# AM13E23219 register map
Vendor: Texas Instruments; File version: 1.0
CPU: CM33 r0p1, little endian, MPU, FPU, VTOR, 4 interrupt priority bits
Registers are 32-bit, read-write, reset 0x0 unless marked. A register's access mark holds for its fields unless they carry their own. Offsets are from the block's base; [hi:lo] are bit positions; {n}, {i} and the like mark numbered series; 'fields as' and 'values as' point back to an identical list.

## SYSCTL (part 2 of 2) — SYSCTL module
Base 0x400AF000
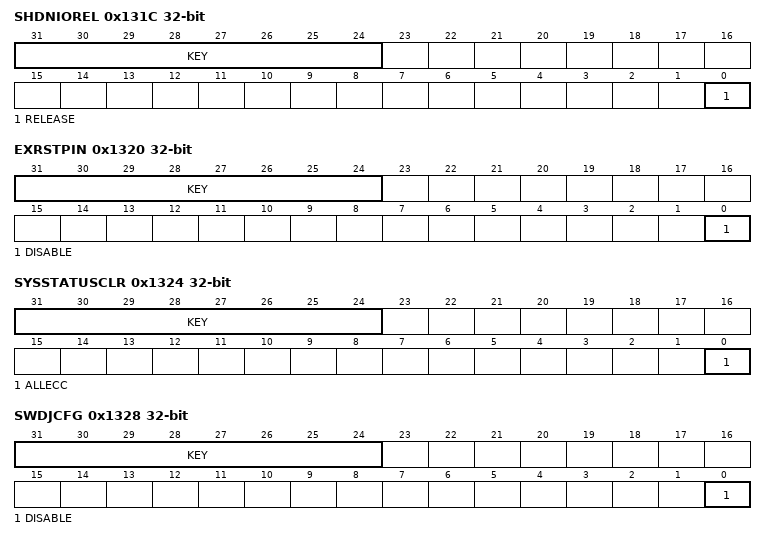
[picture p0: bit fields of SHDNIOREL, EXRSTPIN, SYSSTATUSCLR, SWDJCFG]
0x131C SHDNIOREL access per field — SHUTDOWN IO release control
  [31:24] KEY wo — Key which must be written for the write to take effect.
    145=KEY (Write key.)
  [0] RELEASE rw — Set RELEASE to release the IO after a SHUTDOWN mode exit.
    1=TRUE (Release IO)
0x1320 EXRSTPIN access per field — Disable the reset function of the NRST pin
  [31:24] KEY wo — Key which must be written for the write to take effect.
    30=KEY (Write key.)
  [0] DISABLE rw — Set DISABLE to disable the reset function of the NRST pin. Once set, this configuration is locked until the next POR.
    0=FALSE (Reset function of NRST pin is enabled); 1=TRUE (Reset function of NRST pin is disabled)
0x1324 SYSSTATUSCLR access per field — Clear sticky bits of SYSSTATUS
  [31:24] KEY wo — Key which must be written for the write to take effect.
    206=KEY (Write key.)
  [0] ALLECC rw — Set ALLECC to clear all ECC related SYSSTATUS indicators.
    1=CLEAR (Clear ECC error state)
0x1328 SWDJCFG access per field — Disable the SWD/JTAG function on the SWD/JTAG pins
  [31:24] KEY wo — Key which must be written for the write to take effect.
    98=KEY (Write key.)
  [0] DISABLE rw — Set DISABLE to disable the SWD/JTAG function on SWD/JTAG pins, allowing the SWD/JTAG pins to be used as GPIO.
    1=TRUE (Disable SWD/JTAG function on SWD/JTAG pins)
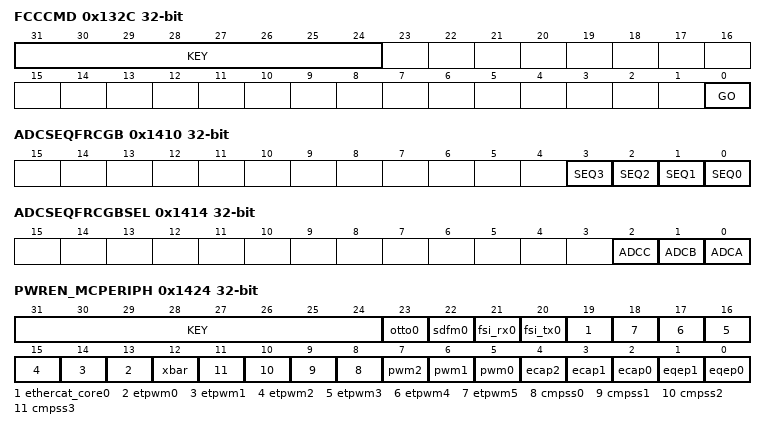
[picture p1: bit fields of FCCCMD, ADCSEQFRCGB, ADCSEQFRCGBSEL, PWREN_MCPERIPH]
0x132C FCCCMD access per field — Frequency clock counter start capture
  [31:24] KEY wo — Key which must be written for the write to take effect.
    14=KEY (Write key.)
  [0] GO rw — Set GO to start a capture with the frequency clock counter (FCC).
    1=TRUE
{0x1400+4i} SHUTDNSTORE{i} (i=0..3) — Shutdown storage memory (byte {i})
  [7:0] DATA — Shutdown storage byte {i}
0x1410 ADCSEQFRCGB — ADC Global Sequence Force
  [n] SEQ{n} (n=0..3) — Generate synchronous SW trigger for SEQ{n}
0x1414 ADCSEQFRCGBSEL — ADC Global Sequence Force Select
  [2] ADCC — Generate synchronous SW trigger for ADCC
  [1] ADCB — Generate synchronous SW trigger for ADCB
  [0] ADCA — Generate synchronous SW trigger for ADCA
0x1418 M33SPARESOCLOCK1 access not given — M33C1 Spare SOC LOCK Reg 1
0x141C M33SPARESOCLOCK2 access not given — M33C1 Spare SOC LOCK Reg 2
0x1420 SYSCTL_READ_REG access not given — Sysctl read only Reg
0x1424 PWREN_MCPERIPH access per field — Register to control the power state
  [31:24] KEY wo — Key which must be written for the write to take effect.
    38=KEY (Write key.)
  [23] otto0 rw — Enable the power to IP, KEY must be set to 26h to write to this bit
    0=Disable Power; 1=Enable Power
  [22] sdfm0 rw — Enable the power to IP, KEY must be set to 26h to write to this bit
    0=Disable Power; 1=Enable Power
  [21] fsi_rx0 rw — Enable the power to IP, KEY must be set to 26h to write to this bit
    0=Disable Power; 1=Enable Power
  [20] fsi_tx0 rw — Enable the power to IP, KEY must be set to 26h to write to this bit
    0=Disable Power; 1=Enable Power
  [19] ethercat_core0 rw — Enable the power to IP, KEY must be set to 26h to write to this bit
    0=Disable Power; 1=Enable Power
  [n+13] etpwm{n} rw (n=0..5) — Enable the power to IP, KEY must be set to 26h to write to this bit
    0=Disable Power; 1=Enable Power
  [12] xbar rw — Enable the power to IP, KEY must be set to 26h to write to this bit
    0=Disable Power; 1=Enable Power
  [n+8] cmpss{n} rw (n=0..3) — Enable the power to IP, KEY must be set to 26h to write to this bit
    0=Disable Power; 1=Enable Power
  [7] pwm2 rw — Enable the power to IP, KEY must be set to 26h to write to this bit
    0=Disable Power; 1=Enable Power
  [6] pwm1 rw — Enable the power to IP, KEY must be set to 26h to write to this bit
    0=Disable Power; 1=Enable Power
  [5] pwm0 rw — Enable the power to IP, KEY must be set to 26h to write to this bit
    0=Disable Power; 1=Enable Power
  [4] ecap2 rw — Enable the power to IP, KEY must be set to 26h to write to this bit
    0=Disable Power; 1=Enable Power
  [3] ecap1 rw — Enable the power to IP, KEY must be set to 26h to write to this bit
    0=Disable Power; 1=Enable Power
  [2] ecap0 rw — Enable the power to IP, KEY must be set to 26h to write to this bit
    0=Disable Power; 1=Enable Power
  [1] eqep1 rw — Enable the power to IP, KEY must be set to 26h to write to this bit
    0=Disable Power; 1=Enable Power
  [0] eqep0 rw — Enable the power to IP, KEY must be set to 26h to write to this bit
    0=Disable Power; 1=Enable Power
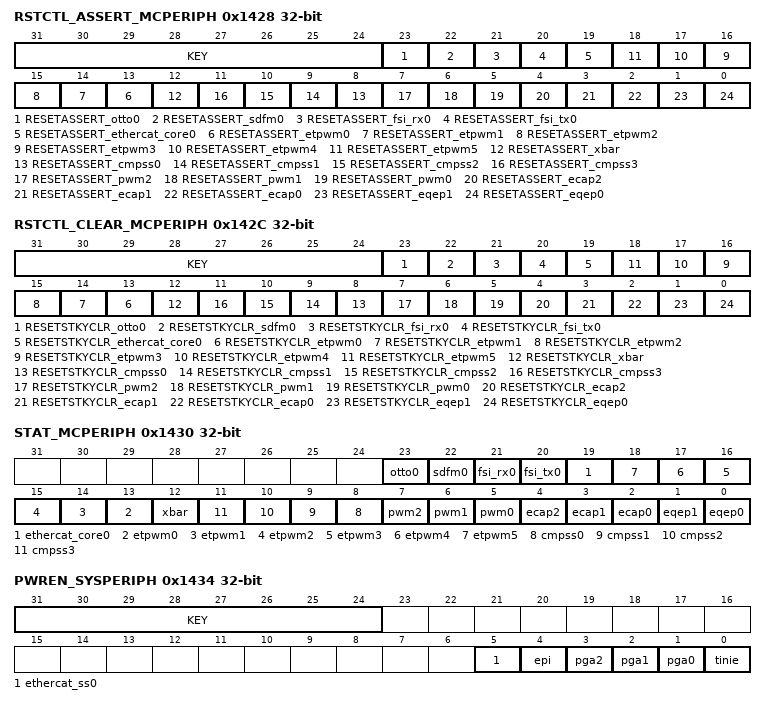
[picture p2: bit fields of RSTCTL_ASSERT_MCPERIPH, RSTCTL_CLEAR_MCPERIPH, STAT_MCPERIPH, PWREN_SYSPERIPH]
0x1428 RSTCTL_ASSERT_MCPERIPH access per field — rstctl assert register to control reset assertion - Write Only Register, Always Read as 0
  [31:24] KEY wo — Key which must be written for the write to take effect.
    177=KEY (Write key.)
  [23] RESETASSERT_otto0 rw — assert reset to the peripheral, KEY must be set to B1h to write to this bit
    0=no_effect (Writing 0 has no effect); 1=Assert reset
  [22] RESETASSERT_sdfm0 rw — assert reset to the peripheral, KEY must be set to B1h to write to this bit
    0=no_effect (Writing 0 has no effect); 1=Assert reset
  [21] RESETASSERT_fsi_rx0 rw — assert reset to the peripheral, KEY must be set to B1h to write to this bit
    0=no_effect (Writing 0 has no effect); 1=Assert reset
  [20] RESETASSERT_fsi_tx0 rw — assert reset to the peripheral, KEY must be set to B1h to write to this bit
    0=no_effect (Writing 0 has no effect); 1=Assert reset
  [19] RESETASSERT_ethercat_core0 rw — assert reset to the peripheral, KEY must be set to B1h to write to this bit
    0=no_effect (Writing 0 has no effect); 1=Assert reset
  [n+13] RESETASSERT_etpwm{n} rw (n=0..5) — assert reset to the peripheral, KEY must be set to B1h to write to this bit
    0=no_effect (Writing 0 has no effect); 1=Assert reset
  [12] RESETASSERT_xbar rw — assert reset to the peripheral, KEY must be set to B1h to write to this bit
    0=no_effect (Writing 0 has no effect); 1=Assert reset
  [n+8] RESETASSERT_cmpss{n} rw (n=0..3) — assert reset to the peripheral, KEY must be set to B1h to write to this bit
    0=no_effect (Writing 0 has no effect); 1=Assert reset
  [7] RESETASSERT_pwm2 rw — assert reset to the peripheral, KEY must be set to B1h to write to this bit
    0=no_effect (Writing 0 has no effect); 1=Assert reset
  [6] RESETASSERT_pwm1 rw — assert reset to the peripheral, KEY must be set to B1h to write to this bit
    0=no_effect (Writing 0 has no effect); 1=Assert reset
  [5] RESETASSERT_pwm0 rw — assert reset to the peripheral, KEY must be set to B1h to write to this bit
    0=no_effect (Writing 0 has no effect); 1=Assert reset
  [4] RESETASSERT_ecap2 rw — assert reset to the peripheral, KEY must be set to B1h to write to this bit
    0=no_effect (Writing 0 has no effect); 1=Assert reset
  [3] RESETASSERT_ecap1 rw — assert reset to the peripheral, KEY must be set to B1h to write to this bit
    0=no_effect (Writing 0 has no effect); 1=Assert reset
  [2] RESETASSERT_ecap0 rw — assert reset to the peripheral, KEY must be set to B1h to write to this bit
    0=no_effect (Writing 0 has no effect); 1=Assert reset
  [1] RESETASSERT_eqep1 rw — assert reset to the peripheral, KEY must be set to B1h to write to this bit
    0=no_effect (Writing 0 has no effect); 1=Assert reset
  [0] RESETASSERT_eqep0 rw — assert reset to the peripheral, KEY must be set to B1h to write to this bit
    0=no_effect (Writing 0 has no effect); 1=Assert reset
0x142C RSTCTL_CLEAR_MCPERIPH access per field — rstctl clear register to control reset de-assertion - Write Only Register, Always Read as 0
  [31:24] KEY wo — Key which must be written for the write to take effect.
    177=KEY (Write key.)
  [23] RESETSTKYCLR_otto0 rw — Clear the RESETSTKY bit in the STAT register, KEY must be set to B1h to write to this bit
    1=Clear reset sticky bit
  [22] RESETSTKYCLR_sdfm0 rw — Clear the RESETSTKY bit in the STAT register, KEY must be set to B1h to write to this bit
    1=Clear reset sticky bit
  [21] RESETSTKYCLR_fsi_rx0 rw — Clear the RESETSTKY bit in the STAT register, KEY must be set to B1h to write to this bit
    1=Clear reset sticky bit
  [20] RESETSTKYCLR_fsi_tx0 rw — Clear the RESETSTKY bit in the STAT register, KEY must be set to B1h to write to this bit
    1=Clear reset sticky bit
  [19] RESETSTKYCLR_ethercat_core0 rw — Clear the RESETSTKY bit in the STAT register, KEY must be set to B1h to write to this bit
    1=Clear reset sticky bit
  [n+13] RESETSTKYCLR_etpwm{n} rw (n=0..5) — Clear the RESETSTKY bit in the STAT register, KEY must be set to B1h to write to this bit
    1=Clear reset sticky bit
  [12] RESETSTKYCLR_xbar rw — Clear the RESETSTKY bit in the STAT register, KEY must be set to B1h to write to this bit
    1=Clear reset sticky bit
  [n+8] RESETSTKYCLR_cmpss{n} rw (n=0..3) — Clear the RESETSTKY bit in the STAT register, KEY must be set to B1h to write to this bit
    1=Clear reset sticky bit
  [7] RESETSTKYCLR_pwm2 rw — Clear the RESETSTKY bit in the STAT register, KEY must be set to B1h to write to this bit
    1=Clear reset sticky bit
  [6] RESETSTKYCLR_pwm1 rw — Clear the RESETSTKY bit in the STAT register, KEY must be set to B1h to write to this bit
    1=Clear reset sticky bit
  [5] RESETSTKYCLR_pwm0 rw — Clear the RESETSTKY bit in the STAT register, KEY must be set to B1h to write to this bit
    1=Clear reset sticky bit
  [4] RESETSTKYCLR_ecap2 rw — Clear the RESETSTKY bit in the STAT register, KEY must be set to B1h to write to this bit
    1=Clear reset sticky bit
  [3] RESETSTKYCLR_ecap1 rw — Clear the RESETSTKY bit in the STAT register, KEY must be set to B1h to write to this bit
    1=Clear reset sticky bit
  [2] RESETSTKYCLR_ecap0 rw — Clear the RESETSTKY bit in the STAT register, KEY must be set to B1h to write to this bit
    1=Clear reset sticky bit
  [1] RESETSTKYCLR_eqep1 rw — Clear the RESETSTKY bit in the STAT register, KEY must be set to B1h to write to this bit
    1=Clear reset sticky bit
  [0] RESETSTKYCLR_eqep0 rw — Clear the RESETSTKY bit in the STAT register, KEY must be set to B1h to write to this bit
    1=Clear reset sticky bit
0x1430 STAT_MCPERIPH ro — IP State Register - Read Only
  [all] fields
    0=clr (The peripheral has not been reset since this bit was last cleared by RESETSTKYCLR in the RSTCTL register); 1=reset (The peripheral was reset since the last bit clear)
  [23] otto0 — This bit indicates, if the peripheral was reset, since this bit was cleared by RESETSTKYCLR in the RSTCTL register
  [22] sdfm0 — This bit indicates, if the peripheral was reset, since this bit was cleared by RESETSTKYCLR in the RSTCTL register
  [21] fsi_rx0 — This bit indicates, if the peripheral was reset, since this bit was cleared by RESETSTKYCLR in the RSTCTL register
  [20] fsi_tx0 — This bit indicates, if the peripheral was reset, since this bit was cleared by RESETSTKYCLR in the RSTCTL register
  [19] ethercat_core0 — This bit indicates, if the peripheral was reset, since this bit was cleared by RESETSTKYCLR in the RSTCTL register
  [n+13] etpwm{n} (n=0..5) — This bit indicates, if the peripheral was reset, since this bit was cleared by RESETSTKYCLR in the RSTCTL register
  [12] xbar — This bit indicates, if the peripheral was reset, since this bit was cleared by RESETSTKYCLR in the RSTCTL register
  [n+8] cmpss{n} (n=0..3) — This bit indicates, if the peripheral was reset, since this bit was cleared by RESETSTKYCLR in the RSTCTL register
  [7] pwm2 — This bit indicates, if the peripheral was reset, since this bit was cleared by RESETSTKYCLR in the RSTCTL register
  [6] pwm1 — This bit indicates, if the peripheral was reset, since this bit was cleared by RESETSTKYCLR in the RSTCTL register
  [5] pwm0 — This bit indicates, if the peripheral was reset, since this bit was cleared by RESETSTKYCLR in the RSTCTL register
  [4] ecap2 — This bit indicates, if the peripheral was reset, since this bit was cleared by RESETSTKYCLR in the RSTCTL register
  [3] ecap1 — This bit indicates, if the peripheral was reset, since this bit was cleared by RESETSTKYCLR in the RSTCTL register
  [2] ecap0 — This bit indicates, if the peripheral was reset, since this bit was cleared by RESETSTKYCLR in the RSTCTL register
  [1] eqep1 — This bit indicates, if the peripheral was reset, since this bit was cleared by RESETSTKYCLR in the RSTCTL register
  [0] eqep0 — This bit indicates, if the peripheral was reset, since this bit was cleared by RESETSTKYCLR in the RSTCTL register
0x1434 PWREN_SYSPERIPH access per field — Register to control the power state
  [31:24] KEY wo — Key which must be written for the write to take effect.
    38=KEY (Write key.)
  [5] ethercat_ss0 rw — Enable the power to IP, KEY must be set to 26h to write to this bit
    0=Disable Power; 1=Enable Power
  [4] epi rw — Enable the power to IP, KEY must be set to 26h to write to this bit
    0=Disable Power; 1=Enable Power
  [3] pga2 rw — Enable the power to IP, KEY must be set to 26h to write to this bit
    0=Disable Power; 1=Enable Power
  [2] pga1 rw — Enable the power to IP, KEY must be set to 26h to write to this bit
    0=Disable Power; 1=Enable Power
  [1] pga0 rw — Enable the power to IP, KEY must be set to 26h to write to this bit
    0=Disable Power; 1=Enable Power
  [0] tinie rw — Enable the power to IP, KEY must be set to 26h to write to this bit
    0=Disable Power; 1=Enable Power
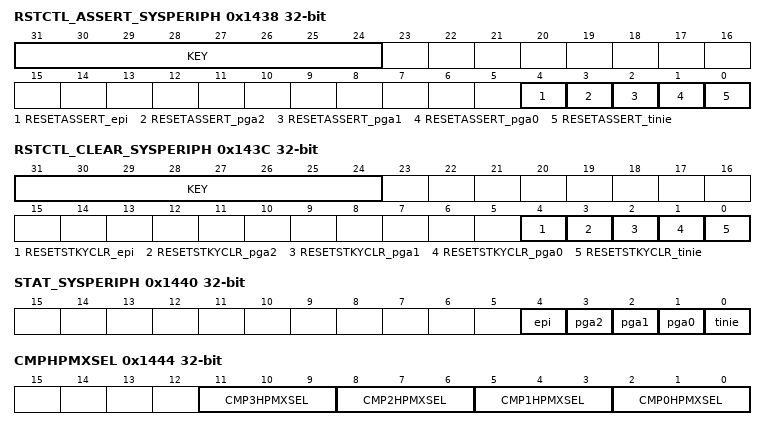
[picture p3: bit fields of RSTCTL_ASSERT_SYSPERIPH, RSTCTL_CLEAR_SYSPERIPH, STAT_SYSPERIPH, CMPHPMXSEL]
0x1438 RSTCTL_ASSERT_SYSPERIPH access per field — rstcl assert Register - Write Only Register, Always Read as 0
  [31:24] KEY wo — Key which must be written for the write to take effect.
    177=KEY (Write key.)
  [4] RESETASSERT_epi rw — assert reset to the peripheral, KEY must be set to B1h to write to this bit
    0=no_effect (Writing 0 has no effect); 1=Assert reset
  [3] RESETASSERT_pga2 rw — assert reset to the peripheral, KEY must be set to B1h to write to this bit
    0=no_effect (Writing 0 has no effect); 1=Assert reset
  [2] RESETASSERT_pga1 rw — assert reset to the peripheral, KEY must be set to B1h to write to this bit
    0=no_effect (Writing 0 has no effect); 1=Assert reset
  [1] RESETASSERT_pga0 rw — assert reset to the peripheral, KEY must be set to B1h to write to this bit
    0=no_effect (Writing 0 has no effect); 1=Assert reset
  [0] RESETASSERT_tinie rw — assert reset to the peripheral, KEY must be set to B1h to write to this bit
    0=no_effect (Writing 0 has no effect); 1=Assert reset
0x143C RSTCTL_CLEAR_SYSPERIPH access per field — rstctl clear register to control reset de-assertion - Write Only Register, Always Read as 0
  [31:24] KEY wo — Key which must be written for the write to take effect.
    177=KEY (Write key.)
  [4] RESETSTKYCLR_epi rw — Clear the RESETSTKY bit in the STAT register, KEY must be set to B1h to write to this bit
    1=Clear reset sticky bit
  [3] RESETSTKYCLR_pga2 rw — Clear the RESETSTKY bit in the STAT register, KEY must be set to B1h to write to this bit
    1=Clear reset sticky bit
  [2] RESETSTKYCLR_pga1 rw — Clear the RESETSTKY bit in the STAT register, KEY must be set to B1h to write to this bit
    1=Clear reset sticky bit
  [1] RESETSTKYCLR_pga0 rw — Clear the RESETSTKY bit in the STAT register, KEY must be set to B1h to write to this bit
    1=Clear reset sticky bit
  [0] RESETSTKYCLR_tinie rw — Clear the RESETSTKY bit in the STAT register, KEY must be set to B1h to write to this bit
    1=Clear reset sticky bit
0x1440 STAT_SYSPERIPH ro — IP State Register - Read Only
  [all] fields
    values as the fields of STAT_MCPERIPH
  [4] epi — This bit indicates, if the peripheral was reset, since this bit was cleared by RESETSTKYCLR in the RSTCTL register
  [3] pga2 — This bit indicates, if the peripheral was reset, since this bit was cleared by RESETSTKYCLR in the RSTCTL register
  [2] pga1 — This bit indicates, if the peripheral was reset, since this bit was cleared by RESETSTKYCLR in the RSTCTL register
  [1] pga0 — This bit indicates, if the peripheral was reset, since this bit was cleared by RESETSTKYCLR in the RSTCTL register
  [0] tinie — This bit indicates, if the peripheral was reset, since this bit was cleared by RESETSTKYCLR in the RSTCTL register
0x1444 CMPHPMXSEL — Bits to select one of the many sources on CompHP inputs. Refer to Pinmux diagram for details.
  [3n+2:3n] CMP{n}HPMXSEL (n=0..3) — CMP{n}HPMXSEL bits
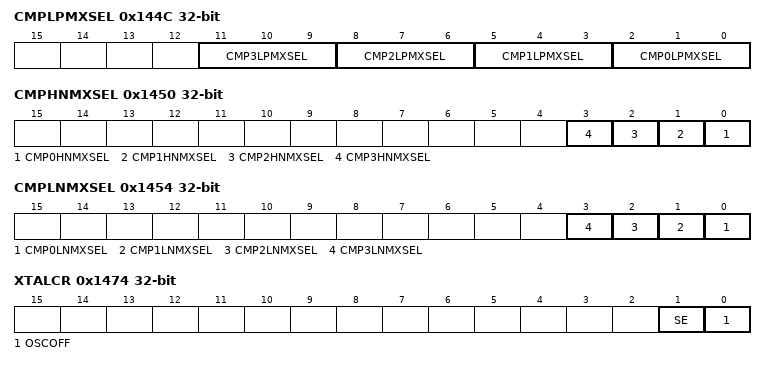
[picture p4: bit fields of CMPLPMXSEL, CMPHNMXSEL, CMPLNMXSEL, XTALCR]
0x144C CMPLPMXSEL — Bits to select one of the many sources on CompLP inputs. Refer to Pinmux diagram for details.
  [3n+2:3n] CMP{n}LPMXSEL (n=0..3) — CMP{n}LPMXSEL bits
0x1450 CMPHNMXSEL — Bits to select one of the many sources on CompHN inputs. Refer to Pinmux diagram for details.
  [n] CMP{n}HNMXSEL (n=0..3) — CMP{n}HNMXSEL bits
0x1454 CMPLNMXSEL — Bits to select one of the many sources on CompLN inputs. Refer to Pinmux diagram for details.
  [n] CMP{n}LNMXSEL (n=0..3) — CMP{n}LNMXSEL bits
0x1458 TSNSCFG access not given — Temperature Sensor Config Register
0x145C TSNSSCTL — Temperature Sensor Control Register
  [0] ENABLE — Temperature Sensor Enable
0x1460 PGACONFIG access not given — PGA Configuration Register
0x1464 REFCONFIGA access not given — Reference Configuration Regsiter
0x1468 INTERNALTESTCTL — Internal Test Node Control Register
  [5:0] TESTSEL — Test Select
    1=SEL1 (VDDCORE); 2=SEL2 (VDDA); 3=SEL3 (VSSA); 4=SEL4 (VREFLOAC); 5=SEL5 (CDAC1H); 6=SEL6 (CDAC1L); {v}=SEL{v} (CDAC2H) (v=7..12); 29=SEL14 (ENZ_CALIB_GAIN_3P3V will be made low. ADCA and ADCC will be in gain calibration mode, and 0.9xVREFHIAB pin voltage will be sampled by both ADCs through internal test-mux output); 30=SEL15 (CMPSS1 VDDA sense on TESTANA0,VSSA sense on TESTANA1); 31=SEL16 (ADCA VDDA sense on TESTANA0,VSSA sense on TESTANA1); 32=SEL17 (COMP DAC BUFFER VDDA sense on TESTANA0,VSSA sense on TESTANA1); 33=SEL18 (PGA1 VDDA sense on TESTANA0,VSSA sense on TESTANA1); 34=SEL19 (ADCCIO_TESTANA0_INT); 35=SEL20 (PMM/HPLL/INTOSC TESTANA0_INT); 36=SEL21 (ADCCIO_TESTANA1_INT); 37=SEL22 (PMM/HPLL/INTOSC TESTANA1_INT); 38=SEL23 (Enable resistor for I2V conversion. The same control enables the sampling of voltage across a resistor by ADC. R=2.5k, 38: R=10k, 39: R=35k); 41=SEL24 (USB_TESTANA0_INT); 42=SEL25 (USB_TESTANA1_INT); 43=SEL26 (USB_TESTANA0_INT & USB_TESTANA1_INT); 44=SEL27 (VSS); 45=SEL28 (Bring FLT3 & TESTPAD3 of flash on TESTANA1); 46=SEL29 (Enable resistor for I2V conversion. The same control enables the sampling of voltage across a resistor by ADC. R=2.5k, 47: R=10k, 48: R=35k); 49=SEL30 (VREFLOAC)
0x146C I2VCTL access not given — I2V Logic Control
0x1470 ADCDACLOOPBACK access not given — Not used in AM13
0x1474 XTALCR — XTAL Control Register
  [1] SE — XTAL Oscilator in Single-Ended
    0=FALSE (XTAL oscillator in Crystal mode); 1=TRUE (XTAL oscilator in single-ended mode (through X1))
  [0] OSCOFF — This bit if 1, powers-down the XTAL oscillator macro and hence doesnt let X2 to be driven by the XTAL oscillator. If a crystal is connected to X1/X2, user needs to first clear this bit, wait for the oscillator to power up (using X1CNT) and then only switch the clock source to X1/X2
    0=FALSE (XTAL Oscillator powered-up using X1/X2); 1=TRUE (XTAL Oscillator powered-down)
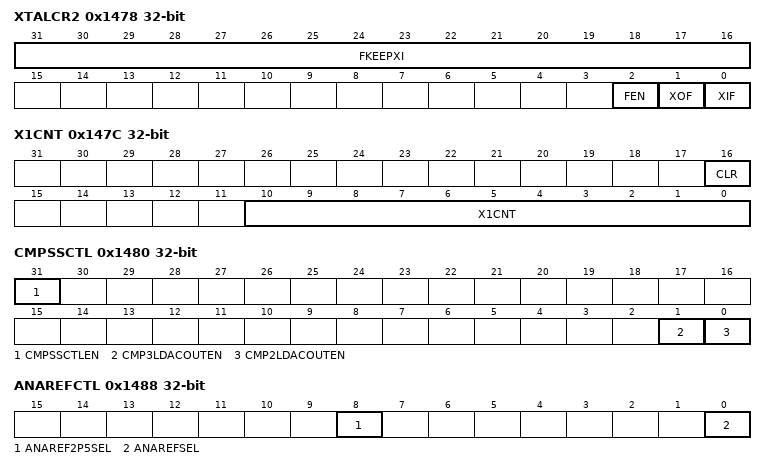
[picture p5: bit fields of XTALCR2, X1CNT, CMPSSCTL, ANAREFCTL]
0x1478 XTALCR2 — XTAL Control Register for pad init
  [31:16] FKEEPXI — This field when written 0xface allows to hold the force value on XI as programmed on XIF. 0xface: Force on XI is continued as per XIF value regardless of XOSC ON/OFF state only in XTAL mode. In Single ended mode this field has no impact. Any other value: Force on XI is removed with enabling of XOSC as per FEN function.
  [2] FEN — XOSC pads initialisation enable. Configures XTAL oscillator pad initilisation. This register has effect only when XOSC is OFF (no SE , no XTAL mode). If this register is set during XOSC off state (XOSCOFF=1 & SE=0); then upon change of these controls this bit gets reset and rearmed
    0=FALSE (XOSC pads are not driven through GPIO connection.); 1=TRUE (XOSC pads are driven through connected GPIO as per XIF & XOF values.)
  [1] XOF — XO Initial value deposited before XOSC start. Polarity selection to initialise XO/X2 pad of the XOSC before start-up. This value shall be deposited on the pad before XOSC started (XOSCOFF=1). If FEN=0 or XOSC is in XTAL or SE mode; then this value will not be applied to the pad.
  [0] XIF — XI Initial value deposited before XOSC start. Polarity selection to initialise XI/X1 pad of the XOSC before start-up. This value shall be deposited on the pad before XOSC started (XOSCOFF=1). If FEN=0 or XOSC is in XTAL or SE mode; then this value will not be applied to the pad.
0x147C X1CNT access per field — x1cnt status register
  [16] CLR rw — X1 Counter clear: A write of 1 to this bit field clears the X1CNT and makes it count from 0x0 again (provided X1 clock is ticking). Writes of 0 are ignore to this bit field
  [10:0] X1CNT ro — This counter increments on every X1 CLOCKs positive-edge. Once it reaches the values of 0x7ff, it freezes. Before switching from SYSOSC/PLL clock to X1, application must check this counter and make sure that it has saturated. This will ensure that the Crystal connected to X1/X2 is oscillating
0x1480 CMPSSCTL — CMPSS control register
  [31] CMPSSCTLEN — Enable the CMPSSCTL Register
  [1] CMP3LDACOUTEN — Enable general purpose DAC functionality for CMPSS3 COMPDACL
  [0] CMP2LDACOUTEN — Enable general purpose DAC functionality for CMPSS2 COMPDACL
0x1484 CMPSSDACBUFCONFIG access not given — Config bits for CMPSS DAC buffer
0x1488 ANAREFCTL — Analog Reference Select
  [8] ANAREF2P5SEL — Analog reference 2.5V source select. In internal reference mode, this bit selects which voltage the internal reference buffer drives onto the VREFHI pin. The buffer can drive either 1.65V onto the pin, resulting in a reference range of 0 to 3.3V, or the buffer can drive 2.5V onto the pin, resulting in a reference range of 0 to 2.5V. If switching between these two modes, the user must allow adequate time for the external capacitor to charge to the new voltage before using the ADC or buffered DAC. 0 - Internal 1.65V reference mode (3.3V reference range) 1 - Internal 2.5V reference mode (2.5V reference range)
  [0] ANAREFSEL — Analog reference mode select. This bit selects whether the VREFHI pin uses internal reference mode (the device drives a voltage onto the VREFHI pin) or external reference mode (the system is expected to drive a voltage into the VREFHI pin). 0 - Internal reference mode 1 - External reference mode
0x148C PERCLKCR — PWM Time Base Clock sync
  [0] TBCLKSYNC — PWM Time Base Clock sync: When set PWM time bases of all the PWM modules belonging to the same CPU-Subsystem (as partitioned using their CPUSEL bits) start counting
0x1490 ADC_MMR_OVRD_CTL access not given — ADC MMR Override control register for DFT: Control ADC enable override
0x1494 ADC_MMR_OVRD_VAL access not given — ADC MMR Override value register for DFT : Value of ADC enable override
0x1498 VREGCONFIGDEBUG access not given — VREG Configuration Debug Register
0x149C VREGCONFIGDFT access not given — VREG Configuration DFT Register
0x14A0 AM13SPAREIREFENSOCLOCK — AM13 Spare IREFEN SOC LOCK Reg
  [5:0] SPARE — Spare IREFEN SOC LOCK Register
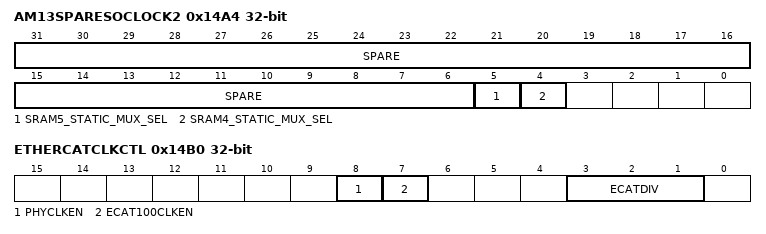
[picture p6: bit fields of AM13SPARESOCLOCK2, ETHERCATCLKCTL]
0x14A4 AM13SPARESOCLOCK2 — AM13 Spare SOC LOCK Reg 2
  [31:6] SPARE — Spare SOC LOCK Register 2
  [5] SRAM5_STATIC_MUX_SEL — SRAM5 static mux select between CBUS and SBUS
    0=SBUS (SBUS path is selected); 1=CBUS (CBUS path is selected)
  [4] SRAM4_STATIC_MUX_SEL — SRAM4 static mux select between CBUS and SBUS
    values as SRAM5_STATIC_MUX_SEL
0x14A8 AM13SPARESOCLOCK3 access not given — AM13 Spare SOC LOCK Reg 3
0x14AC AM13SPARESOCLOCK4 access not given — AM13 Spare SOC LOCK Reg 4
0x14B0 ETHERCATCLKCTL — EtherCAT Clock Control
  [8] PHYCLKEN — etherCAT PHY clock enable
    0=DISABLE (etherCAT phy clock disabled); 1=ENABLE (etherCAT phy clock enabled)
  [7] ECAT100CLKEN — etherCAT 100 clock enable
    0=DISABLE (etherCAT 100 clock disabled); 1=ENABLE (etherCAT 100 clock enabled)
  [3:1] ECATDIV — etherCAT clock divider configuration
0x14B4 ETHERCATCTL — ETHERCAT control register
  [8] I2CLOOPBACK — Loopback I2C port of etherCAT IP to I2C_A
    0=DISABLE (I2C port of etherCAT is not looped back to I2C_A); 1=ENABLE (I2C port of etherCAT is looped back to I2C_A)
0x14B8 SDFMTYPE — Configures SDFM type for the device
  [1:0] SDFMTYPE — Based on the configuration enables or disables features associated with the SDFM type.
    0=TYPE0 (1. Data Ready conditions combined with the fault conditions on the SDFM interrupt line. 2. Data ready interrupts from individual filters are not generated.); 1=TYPE1 (1. Data Ready conditions do not generate the SDFMINT. 2. Each filter generates a separate data ready interrupts.); 10=TYPE2 (1. Data Ready conditions combined with the fault conditions on the SDFM interrupt line. 2. Data ready interrupts from individual filters are not generated.); 11=TYPE3 (1. Data Ready conditions combined with the fault conditions on the SDFM interrupt line. 2. Data ready interrupts from individual filters are not generated.)
